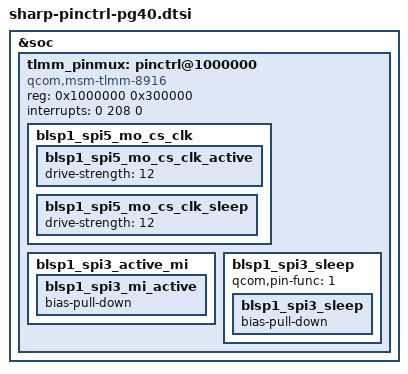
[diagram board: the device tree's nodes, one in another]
/* Copyright (c) 2013-2014, The Linux Foundation. All rights reserved.
 *
 * This program is free software; you can redistribute it and/or modify
 * it under the terms of the GNU General Public License version 2 and
 * only version 2 as published by the Free Software Foundation.
 *
 * This program is distributed in the hope that it will be useful,
 * but WITHOUT ANY WARRANTY; without even the implied warranty of
 * MERCHANTABILITY or FITNESS FOR A PARTICULAR PURPOSE.  See the
 * GNU General Public License for more details.
 */
#include "sharp-pinctrl-shflip.dtsi"
#include "sharp-pinctrl-shswic.dtsi"
#include "sharp-pinctrl-shtrpd.dtsi"
#include "sharp-pinctrl-gpio-keys.dtsi"
#include "dtv_pinctrl_pg40.dtsi"
#include "camera_pinctrl_pg40.dtsi"
#include "sharp-pinctrl-bdic.dtsi"
#include "sharp-pinctrl-pg40-sdcc.dtsi"
#include "sharp-pinctrl-shmds.dtsi"
#include "sharp-pinctrl-shub.dtsi"

&soc {
	tlmm_pinmux: pinctrl@1000000 {
		compatible = "qcom,msm-tlmm-8916";
		reg = <0x1000000 0x300000>;
		interrupts = <0 208 0>;

		blsp1_spi5_mo_cs_clk {
			blsp1_spi5_mo_cs_clk_active: blsp1_spi5_mo_cs_clk_active {
		       drive-strength = <12>;
	        };

			blsp1_spi5_mo_cs_clk_sleep: blsp1_spi5_mo_cs_clk_sleep {
		       drive-strength = <12>;
	        };
		};

		/*****************************************/
		/*  SPI                                  */
		/*****************************************/
		blsp1_spi3_active_mi {
			blsp1_spi3_mi_active: blsp1_spi3_mi_active {
				/delete-property/ bias-pull-up;
				bias-pull-down;
			};
		};

		blsp1_spi3_sleep {
			qcom,pin-func = <1>;
			blsp1_spi3_sleep: blsp1_spi3_sleep {
				/delete-property/ bias-pull-up;
				bias-pull-down;
			};
		};

	};
};
